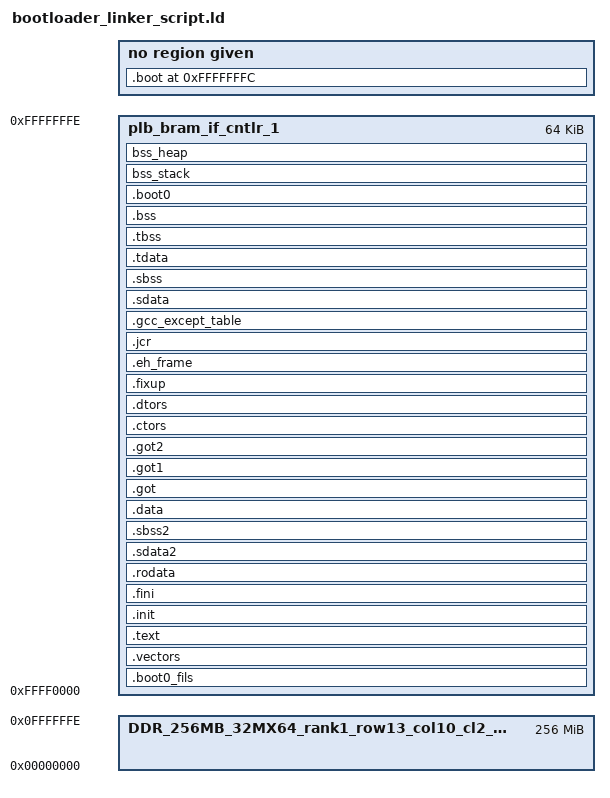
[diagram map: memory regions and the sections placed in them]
/*******************************************************************/
/*                                                                 */
/* This file is automatically generated by linker script generator.*/
/*                                                                 */
/* Version: Xilinx EDK 8.1.02EDK_I.20.4                                  */
/*                                                                 */
/* Copyright (c) 2004 Xilinx, Inc.  All rights reserved.           */
/*                                                                 */
/* Description : PowerPC405 Linker Script                         */
/*                                                                 */
/*******************************************************************/

_STACK_SIZE = DEFINED(_STACK_SIZE) ? _STACK_SIZE : 0x4000;
_HEAP_SIZE = DEFINED(_HEAP_SIZE) ? _HEAP_SIZE : 0x400;

/* Define Memories in the system */

MEMORY
{
   DDR_256MB_32MX64_rank1_row13_col10_cl2_5_C_MEM0_BASEADDR : ORIGIN = 0x00000000, LENGTH = 0x0FFFFFFF
   plb_bram_if_cntlr_1 : ORIGIN = 0xFFFF0000, LENGTH = 0x0000FFFF
}

/* Specify the default entry point to the program */

ENTRY(_boot)
STARTUP(boot.o)

/* Define the sections, and where they are mapped in memory */

SECTIONS
{
.boot0_fils : {
   __boot0_fils_start = .;
   *(.boot0_fils)
   __boot0_fils_end = .;
} > plb_bram_if_cntlr_1

.vectors : {
   __vectors_start = .;
   *(.vectors)
   __vectors_end = .;
} > plb_bram_if_cntlr_1

.text : {
   *(.text)
   *(.text.*)
   *(.gnu.linkonce.t.*)
} > plb_bram_if_cntlr_1

.init : {
   KEEP (*(.init))
} > plb_bram_if_cntlr_1

.fini : {
   KEEP (*(.fini))
} > plb_bram_if_cntlr_1

.rodata : {
   __rodata_start = .;
   *(.rodata)
   *(.rodata.*)
   *(.gnu.linkonce.r.*)
   __rodata_end = .;
} > plb_bram_if_cntlr_1

.sdata2 : {
   __sdata2_start = .;
   *(.sdata2)
   *(.gnu.linkonce.s2.*)
   __sdata2_end = .;
} > plb_bram_if_cntlr_1

.sbss2 : {
   __sbss2_start = .;
   *(.sbss2)
   *(.gnu.linkonce.sb2.*)
   __sbss2_end = .;
} > plb_bram_if_cntlr_1

.data : {
   __data_start = .;
   *(.data)
   *(.data.*)
   *(.gnu.linkonce.d.*)
   __data_end = .;
} > plb_bram_if_cntlr_1

.got : {
   *(.got)
} > plb_bram_if_cntlr_1

.got1 : {
   *(.got1)
} > plb_bram_if_cntlr_1

.got2 : {
   *(.got2)
} > plb_bram_if_cntlr_1

.ctors : {
   __CTOR_LIST__ = .;
   ___CTORS_LIST___ = .;
   KEEP (*crtbegin.o(.ctors))
   KEEP (*(EXCLUDE_FILE(*crtend.o) .ctors))
   KEEP (*(SORT(.ctors.*)))
   KEEP (*(.ctors))
   __CTOR_END__ = .;
   ___CTORS_END___ = .;
} > plb_bram_if_cntlr_1

.dtors : {
   __DTOR_LIST__ = .;
   ___DTORS_LIST___ = .;
   KEEP (*crtbegin.o(.dtors))
   KEEP (*(EXCLUDE_FILE(*crtend.o) .dtors))
   KEEP (*(SORT(.dtors.*)))
   KEEP (*(.dtors))
   __DTOR_END__ = .;
   ___DTORS_END___ = .;
} > plb_bram_if_cntlr_1

.fixup : {
   __fixup_start = .;
   *(.fixup)
   __fixup_end = .;
} > plb_bram_if_cntlr_1

.eh_frame : {
   *(.eh_frame)
} > plb_bram_if_cntlr_1

.jcr : {
   *(.jcr)
} > plb_bram_if_cntlr_1

.gcc_except_table : {
   *(.gcc_except_table)
} > plb_bram_if_cntlr_1

.sdata : {
   __sdata_start = .;
   *(.sdata)
   *(.gnu.linkonce.s.*)
   __sdata_end = .;
} > plb_bram_if_cntlr_1

.sbss : {
   __sbss_start = .;
   *(.sbss)
   *(.gnu.linkonce.sb.*)
   __sbss_end = .;
} > plb_bram_if_cntlr_1

.tdata : {
   __tdata_start = .;
   *(.tdata)
   *(.gnu.linkonce.td.*)
   __tdata_end = .;
} > plb_bram_if_cntlr_1

.tbss : {
   __tbss_start = .;
   *(.tbss)
   *(.gnu.linkonce.tb.*)
   __tbss_end = .;
} > plb_bram_if_cntlr_1

.bss : {
   __bss_start = .;
   *(.bss)
   *(.gnu.linkonce.b.*)
   *(COMMON)
   . = ALIGN(4);
   __bss_end = .;
} > plb_bram_if_cntlr_1

.boot0 : {
   __boot0_start = .;
   *(.boot0)
   __boot0_end = .;
} > plb_bram_if_cntlr_1

.boot 0xFFFFFFFC : {
   __boot_start = .;
   *(.boot)
   __boot_end = .;
} 

/* Generate Stack and Heap Sections */

bss_stack : {
   . += _STACK_SIZE;
   . = ALIGN(16);
   __stack = .;
} > plb_bram_if_cntlr_1

bss_heap : {
   . = ALIGN(16);
   _heap_start = .;
   . += _HEAP_SIZE;
   . = ALIGN(16);
   _heap_end = .;
} > plb_bram_if_cntlr_1

}

